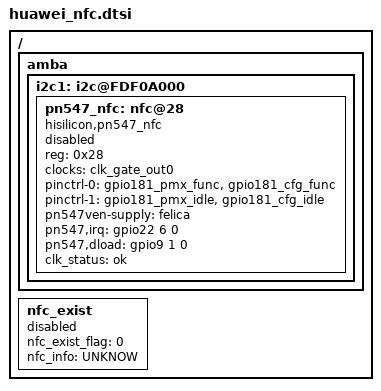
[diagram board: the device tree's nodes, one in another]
/{
	amba {
		i2c1: i2c@FDF0A000 {
			pn547_nfc:nfc@28 {
				compatible = "hisilicon,pn547_nfc";
				reg = <0x28>;
				clocks = <&clk_gate_out0>;
				clock-names = "clk_out0";
				pinctrl-names = "default","idle";
				pinctrl-0 = <&gpio181_pmx_func &gpio181_cfg_func >;
				pinctrl-1 = <&gpio181_pmx_idle &gpio181_cfg_idle>;
				pn547ven-supply = <&felica>;
				pn547,irq = <&gpio22 6 0>;
				pn547,dload = <&gpio9 1 0>;
				clk_status="ok";
				status = "disabled";
			};
		};
	};
	nfc_exist {
		nfc_exist_flag = "0";
		nfc_info = "UNKNOW";
		status = "disabled";
	};
};
